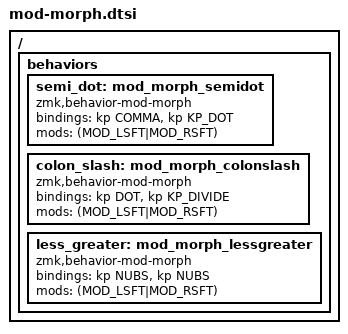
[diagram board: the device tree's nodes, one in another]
/ {
    behaviors {
        semi_dot: mod_morph_semidot {
            compatible = "zmk,behavior-mod-morph";
            #binding-cells = <0>;
            bindings = <&kp COMMA &kp KP_DOT>;
            mods = <(MOD_LSFT|MOD_RSFT)>;
        };

        colon_slash: mod_morph_colonslash {
            compatible = "zmk,behavior-mod-morph";
            #binding-cells = <0>;
            bindings = <&kp DOT &kp KP_DIVIDE>;
            mods = <(MOD_LSFT|MOD_RSFT)>;
        };

        less_greater: mod_morph_lessgreater {
            compatible = "zmk,behavior-mod-morph";
            #binding-cells = <0>;
            bindings = <&kp NUBS &kp NUBS>;
            mods = <(MOD_LSFT|MOD_RSFT)>;
        };
    };
};
